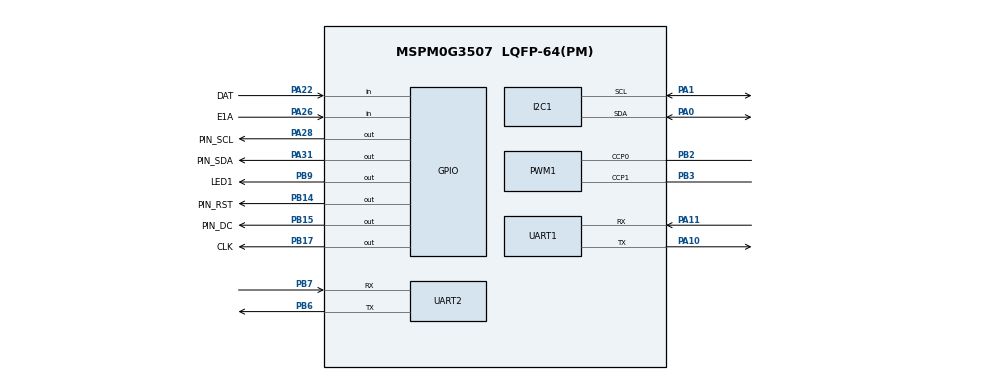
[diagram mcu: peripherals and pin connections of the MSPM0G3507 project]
/**
 * These arguments were used when this file was generated. They will be automatically applied on subsequent loads
 * via the GUI or CLI. Run CLI with '--help' for additional information on how to override these arguments.
 * @cliArgs --device "MSPM0G350X" --part "Default" --package "LQFP-64(PM)" --product "mspm0_sdk@2.10.00.04"
 * @v2CliArgs --device "MSPM0G3507" --package "LQFP-64(PM)" --product "mspm0_sdk@2.10.00.04"
 * @versions {"tool":"1.27.0+4565"}
 */

/**
 * Import the modules used in this configuration.
 */
const GPIO    = scripting.addModule("/ti/driverlib/GPIO", {}, false);
const GPIO1   = GPIO.addInstance();
const GPIO2   = GPIO.addInstance();
const GPIO3   = GPIO.addInstance();
const GPIO4   = GPIO.addInstance();
const GPIO5   = GPIO.addInstance();
const GPIO6   = GPIO.addInstance();
const GPIO7   = GPIO.addInstance();
const GPIO8   = GPIO.addInstance();
const GPIO9   = GPIO.addInstance();
const I2C     = scripting.addModule("/ti/driverlib/I2C", {}, false);
const I2C1    = I2C.addInstance();
const PWM     = scripting.addModule("/ti/driverlib/PWM", {}, false);
const PWM1    = PWM.addInstance();
const SYSCTL  = scripting.addModule("/ti/driverlib/SYSCTL");
const SYSTICK = scripting.addModule("/ti/driverlib/SYSTICK");
const UART    = scripting.addModule("/ti/driverlib/UART", {}, false);
const UART1   = UART.addInstance();
const UART2   = UART.addInstance();

/**
 * Write custom configuration values to the imported modules.
 */
const divider6       = system.clockTree["PLL_CLK2X_DIV"];
divider6.divideValue = 4;

const divider7       = system.clockTree["PLL_PDIV"];
divider7.divideValue = 2;

const divider9       = system.clockTree["UDIV"];
divider9.divideValue = 2;

const multiplier2         = system.clockTree["PLL_QDIV"];
multiplier2.multiplyValue = 10;

const mux8       = system.clockTree["HSCLKMUX"];
mux8.inputSelect = "HSCLKMUX_SYSPLL2X";

GPIO1.$name                          = "AIN";
GPIO1.port                           = "PORTA";
GPIO1.associatedPins.create(2);
GPIO1.associatedPins[0].initialValue = "SET";
GPIO1.associatedPins[0].assignedPin  = "14";
GPIO1.associatedPins[0].$name        = "AIN2";
GPIO1.associatedPins[1].initialValue = "SET";
GPIO1.associatedPins[1].assignedPin  = "13";
GPIO1.associatedPins[1].$name        = "AIN1";

const Board = scripting.addModule("/ti/driverlib/Board", {}, false);

GPIO2.$name                          = "BIN";
GPIO2.port                           = "PORTA";
GPIO2.associatedPins.create(2);
GPIO2.associatedPins[0].initialValue = "SET";
GPIO2.associatedPins[0].assignedPin  = "16";
GPIO2.associatedPins[0].$name        = "BIN2";
GPIO2.associatedPins[1].initialValue = "SET";
GPIO2.associatedPins[1].assignedPin  = "17";
GPIO2.associatedPins[1].$name        = "BIN1";

GPIO3.$name                          = "LED";
GPIO3.associatedPins[0].$name        = "LED1";
GPIO3.associatedPins[0].initialValue = "SET";
GPIO3.associatedPins[0].assignedPort = "PORTB";
GPIO3.associatedPins[0].assignedPin  = "9";
GPIO3.associatedPins[0].pin.$assign  = "PB9";

GPIO4.$name                          = "ENCODER";
GPIO4.associatedPins.create(4);
GPIO4.associatedPins[0].direction    = "INPUT";
GPIO4.associatedPins[0].interruptEn  = true;
GPIO4.associatedPins[0].polarity     = "RISE_FALL";
GPIO4.associatedPins[0].assignedPin  = "25";
GPIO4.associatedPins[0].$name        = "E1B";
GPIO4.associatedPins[1].direction    = "INPUT";
GPIO4.associatedPins[1].interruptEn  = true;
GPIO4.associatedPins[1].polarity     = "RISE_FALL";
GPIO4.associatedPins[1].assignedPin  = "26";
GPIO4.associatedPins[1].$name        = "E1A";
GPIO4.associatedPins[1].pin.$assign  = "PA26";
GPIO4.associatedPins[2].direction    = "INPUT";
GPIO4.associatedPins[2].interruptEn  = true;
GPIO4.associatedPins[2].polarity     = "RISE_FALL";
GPIO4.associatedPins[2].assignedPort = "PORTB";
GPIO4.associatedPins[2].assignedPin  = "20";
GPIO4.associatedPins[2].$name        = "E2B";
GPIO4.associatedPins[3].direction    = "INPUT";
GPIO4.associatedPins[3].interruptEn  = true;
GPIO4.associatedPins[3].polarity     = "RISE_FALL";
GPIO4.associatedPins[3].assignedPort = "PORTB";
GPIO4.associatedPins[3].assignedPin  = "24";
GPIO4.associatedPins[3].$name        = "E2A";

GPIO5.$name                          = "GRAY_SERIAL";
GPIO5.associatedPins.create(2);
GPIO5.associatedPins[0].$name        = "DAT";
GPIO5.associatedPins[0].direction    = "INPUT";
GPIO5.associatedPins[0].assignedPort = "PORTA";
GPIO5.associatedPins[0].assignedPin  = "22";
GPIO5.associatedPins[0].pin.$assign  = "PA22";
GPIO5.associatedPins[1].$name        = "CLK";
GPIO5.associatedPins[1].initialValue = "SET";
GPIO5.associatedPins[1].assignedPort = "PORTB";
GPIO5.associatedPins[1].assignedPin  = "17";
GPIO5.associatedPins[1].pin.$assign  = "PB17";

GPIO6.$name                          = "OLED_RST";
GPIO6.associatedPins[0].$name        = "PIN_RST";
GPIO6.associatedPins[0].initialValue = "SET";
GPIO6.associatedPins[0].assignedPort = "PORTB";
GPIO6.associatedPins[0].assignedPin  = "14";
GPIO6.associatedPins[0].pin.$assign  = "PB14";

GPIO7.$name                          = "OLED_DC";
GPIO7.associatedPins[0].$name        = "PIN_DC";
GPIO7.associatedPins[0].initialValue = "SET";
GPIO7.associatedPins[0].assignedPort = "PORTB";
GPIO7.associatedPins[0].assignedPin  = "15";
GPIO7.associatedPins[0].pin.$assign  = "PB15";

GPIO8.$name                          = "OLED_SCL";
GPIO8.associatedPins[0].$name        = "PIN_SCL";
GPIO8.associatedPins[0].initialValue = "SET";
GPIO8.associatedPins[0].assignedPort = "PORTA";
GPIO8.associatedPins[0].assignedPin  = "28";
GPIO8.associatedPins[0].pin.$assign  = "PA28";

GPIO9.$name                          = "OLED_SDA";
GPIO9.associatedPins[0].$name        = "PIN_SDA";
GPIO9.associatedPins[0].initialValue = "SET";
GPIO9.associatedPins[0].assignedPort = "PORTA";
GPIO9.associatedPins[0].assignedPin  = "31";
GPIO9.associatedPins[0].pin.$assign  = "PA31";

I2C1.$name                             = "I2C_ICM42688";
I2C1.basicEnableController             = true;
I2C1.peripheral.$assign                = "I2C0";
I2C1.peripheral.sdaPin.$assign         = "PA0";
I2C1.peripheral.sclPin.$assign         = "PA1";
I2C1.sdaPinConfig.hideOutputInversion  = scripting.forceWrite(false);
I2C1.sdaPinConfig.onlyInternalResistor = scripting.forceWrite(false);
I2C1.sdaPinConfig.passedPeripheralType = scripting.forceWrite("Digital");
I2C1.sdaPinConfig.$name                = "ti_driverlib_gpio_GPIOPinGeneric4";
I2C1.sclPinConfig.hideOutputInversion  = scripting.forceWrite(false);
I2C1.sclPinConfig.onlyInternalResistor = scripting.forceWrite(false);
I2C1.sclPinConfig.passedPeripheralType = scripting.forceWrite("Digital");
I2C1.sclPinConfig.$name                = "ti_driverlib_gpio_GPIOPinGeneric5";

PWM1.$name                              = "PWM";
PWM1.timerCount                         = 4000;
PWM1.timerStartTimer                    = true;
PWM1.peripheral.$assign                 = "TIMG6";
PWM1.peripheral.ccp0Pin.$assign         = "PB2";
PWM1.peripheral.ccp1Pin.$assign         = "PB3";
PWM1.PWM_CHANNEL_0.$name                = "ti_driverlib_pwm_PWMTimerCC0";
PWM1.PWM_CHANNEL_0.ccValue              = 2000;
PWM1.PWM_CHANNEL_0.invert               = true;
PWM1.PWM_CHANNEL_1.$name                = "ti_driverlib_pwm_PWMTimerCC1";
PWM1.PWM_CHANNEL_1.invert               = true;
PWM1.PWM_CHANNEL_1.ccValue              = 2000;
PWM1.ccp0PinConfig.direction            = scripting.forceWrite("OUTPUT");
PWM1.ccp0PinConfig.hideOutputInversion  = scripting.forceWrite(false);
PWM1.ccp0PinConfig.onlyInternalResistor = scripting.forceWrite(false);
PWM1.ccp0PinConfig.passedPeripheralType = scripting.forceWrite("Digital");
PWM1.ccp0PinConfig.$name                = "ti_driverlib_gpio_GPIOPinGeneric0";
PWM1.ccp1PinConfig.direction            = scripting.forceWrite("OUTPUT");
PWM1.ccp1PinConfig.hideOutputInversion  = scripting.forceWrite(false);
PWM1.ccp1PinConfig.onlyInternalResistor = scripting.forceWrite(false);
PWM1.ccp1PinConfig.passedPeripheralType = scripting.forceWrite("Digital");
PWM1.ccp1PinConfig.$name                = "ti_driverlib_gpio_GPIOPinGeneric1";

SYSCTL.forceDefaultClkConfig = true;
SYSCTL.clockTreeEn           = true;

SYSTICK.periodEnable    = true;
SYSTICK.interruptEnable = true;
SYSTICK.period          = 80000;
SYSTICK.systickEnable   = true;

UART1.$name                            = "UART0";
UART1.targetBaudRate                   = 115200;
UART1.peripheral.$assign               = "UART0";
UART1.peripheral.rxPin.$assign         = "PA11";
UART1.peripheral.txPin.$assign         = "PA10";
UART1.txPinConfig.direction            = scripting.forceWrite("OUTPUT");
UART1.txPinConfig.hideOutputInversion  = scripting.forceWrite(false);
UART1.txPinConfig.onlyInternalResistor = scripting.forceWrite(false);
UART1.txPinConfig.passedPeripheralType = scripting.forceWrite("Digital");
UART1.txPinConfig.$name                = "ti_driverlib_gpio_GPIOPinGeneric2";
UART1.rxPinConfig.hideOutputInversion  = scripting.forceWrite(false);
UART1.rxPinConfig.onlyInternalResistor = scripting.forceWrite(false);
UART1.rxPinConfig.passedPeripheralType = scripting.forceWrite("Digital");
UART1.rxPinConfig.$name                = "ti_driverlib_gpio_GPIOPinGeneric3";

UART2.$name                    = "UART_1";
UART2.enabledInterrupts        = ["RX"];
UART2.interruptPriority        = "1";
UART2.peripheral.$assign       = "UART1";
UART2.peripheral.rxPin.$assign = "PB7";
UART2.peripheral.txPin.$assign = "PB6";
UART2.txPinConfig.$name        = "ti_driverlib_gpio_GPIOPinGeneric6";
UART2.rxPinConfig.$name        = "ti_driverlib_gpio_GPIOPinGeneric7";

/**
 * Pinmux solution for unlocked pins/peripherals. This ensures that minor changes to the automatic solver in a future
 * version of the tool will not impact the pinmux you originally saw.  These lines can be completely deleted in order to
 * re-solve from scratch.
 */
GPIO1.associatedPins[0].pin.$suggestSolution = "PA14";
GPIO1.associatedPins[1].pin.$suggestSolution = "PA13";
Board.peripheral.$suggestSolution            = "DEBUGSS";
Board.peripheral.swclkPin.$suggestSolution   = "PA20";
Board.peripheral.swdioPin.$suggestSolution   = "PA19";
GPIO2.associatedPins[0].pin.$suggestSolution = "PA16";
GPIO2.associatedPins[1].pin.$suggestSolution = "PA17";
GPIO4.associatedPins[0].pin.$suggestSolution = "PA25";
GPIO4.associatedPins[2].pin.$suggestSolution = "PB20";
GPIO4.associatedPins[3].pin.$suggestSolution = "PB24";
